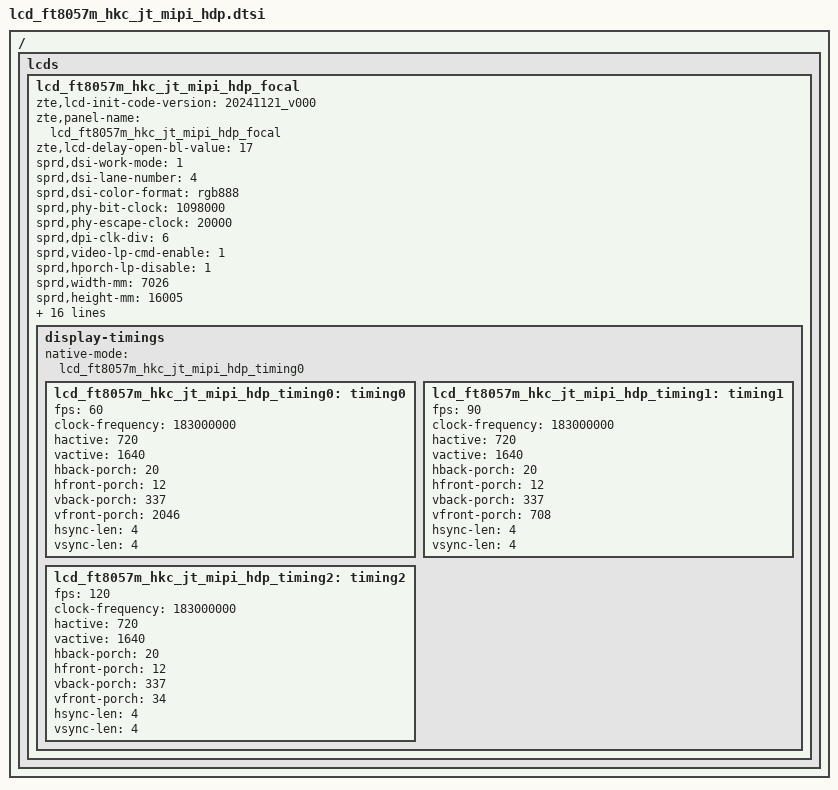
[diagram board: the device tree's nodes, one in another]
/ { 
	fragment {
		target-path = "/";
		__overlay__ {
			lcds {
				lcd_ft8057m_hkc_jt_mipi_hdp_focal: lcd_ft8057m_hkc_jt_mipi_hdp_focal {
		zte,lcd-init-code-version = "20241121_v000";
		zte,panel-name = "lcd_ft8057m_hkc_jt_mipi_hdp_focal";
		zte,lcd-delay-open-bl-value = <17>;

					sprd,dsi-work-mode = <1>;
					sprd,dsi-lane-number = <4>;
					sprd,dsi-color-format = "rgb888";

					sprd,phy-bit-clock = <1098000>;
					sprd,phy-escape-clock = <20000>;
					sprd,dpi-clk-div = <6>;
					sprd,video-lp-cmd-enable = <1>;
					sprd,hporch-lp-disable = <1>;
					sprd,width-mm = <7026>;/*zte mod for 6.67*/
					sprd,height-mm = <16005>;/*zte mod for 6.67*/

					sprd,esd-check-enable = <1>;
					sprd,esd-check-mode = <0>;
					sprd,esd-check-period = <2000>;
					sprd,esd-check-register = <0x0E>;
					sprd,esd-check-value = <0x80>;

					sprd,lcm-ic-name = "FT8057M";
					sprd,lcm-ic-vendor = "JT-HKC";
					sprd,lcm-ic-inch = "6.56";

					sprd,reset-on-sequence = <1 5>, <0 5>, <1 20>;
					sprd,reset-off-sequence = <1 5>;


					sprd,initial-command = [
23 00 00 02 00 00 
39 00 00 04 FF 80 57 01 
23 00 00 02 00 80 
39 00 00 03 FF 80 57 
23 00 00 02 00 00 
39 00 00 05 2A 00 00 02 CF 
23 00 00 02 00 00 
39 00 00 05 2B 00 00 06 67 
23 00 00 02 00 A3 
39 00 00 05 B3 06 68 00 18 
23 00 00 02 00 93 
23 00 00 02 C5 75 
23 00 00 02 00 97 
23 00 00 02 C5 75 
23 00 00 02 00 9A 
23 00 00 02 C5 41 
23 00 00 02 00 9C 
23 00 00 02 C5 41 
23 00 00 02 00 B6 
39 00 00 03 C5 61 61 
23 00 00 02 00 B8 
39 00 00 03 C5 37 37 
23 00 00 02 00 00 
39 00 00 03 D8 37 37 
//23 00 00 02 00 00 
//39 00 00 03 D9 00 AC 
//23 00 00 02 00 00 
//39 00 00 04 D9 00 AC AC 
23 00 00 02 00 82 
23 00 00 02 C5 55 
23 00 00 02 00 83 
23 00 00 02 C5 07 
23 00 00 02 00 96 
23 00 00 02 F5 19 
23 00 00 02 00 86 
23 00 00 02 F5 19 
23 00 00 02 00 94 
23 00 00 02 C5 13 
23 00 00 02 00 9B 
23 00 00 02 C5 31 
23 00 00 02 00 A3 
23 00 00 02 A5 04 
23 00 00 02 00 99 
23 00 00 02 CF 56 
23 00 00 02 00 86 
23 00 00 02 B7 80 
23 00 00 02 00 A5 
23 00 00 02 B0 0D 
23 00 00 02 00 90 
23 00 00 02 FF 00 
23 00 00 02 00 00 
39 00 00 11 E1 00 0B 15 24 2E 38 49 58 59 67 6B 81 80 6B 6B 5F 
23 00 00 02 00 10 
39 00 00 09 E1 57 4B 3C 32 2A 1B 13 0F 
23 00 00 02 00 00 
39 00 00 11 E2 00 0B 15 24 2E 38 49 58 59 67 6B 81 80 6B 6B 5F 
23 00 00 02 00 10 
39 00 00 09 E2 57 4B 3C 32 2A 1B 13 0F 
23 00 00 02 00 80 
23 00 00 02 CE 00 
23 00 00 02 00 D0 
23 00 00 02 CE 01 
23 00 00 02 00 E0 
23 00 00 02 CE 00 
23 00 00 02 00 A1 
23 00 00 02 C1 CC 
23 00 00 02 00 A5 
39 00 00 03 C1 01 43 
23 00 00 02 00 70 
39 00 00 07 C0 00 5F 01 54 00 22 
23 00 00 02 00 D1 
39 00 00 08 CE 00 14 01 01 01 3B 01 
23 00 00 02 00 E8 
39 00 00 05 CE 01 3B 01 3B 
23 00 00 02 00 B0 
39 00 00 06 C0 00 5F 01 55 22 
23 00 00 02 00 80 
39 00 00 03 C1 22 22 
23 00 00 02 00 90 
23 00 00 02 C1 02 
23 00 00 02 00 F1 
23 00 00 02 CF 78 
23 00 00 02 00 F5 
23 00 00 02 CF 00 
23 00 00 02 00 F6 
23 00 00 02 CF 78 
23 00 00 02 00 F7 
23 00 00 02 CF 11 
23 00 00 02 00 70 
39 00 00 09 CF 06 06 8E 92 02 02 3E 42 
23 00 00 02 00 C0 
39 00 00 05 CF 03 03 D8 DC 
23 00 00 02 00 C5 
39 00 00 05 CF 06 06 72 76 
23 00 00 02 00 80 
39 00 00 11 CC 00 00 1C 1C 26 26 01 01 07 09 0B 0D 0F 11 13 15 
23 00 00 02 00 90 
39 00 00 09 CC 05 03 00 00 00 00 00 00 
23 00 00 02 00 80 
39 00 00 11 CD 00 00 1C 1C 26 26 01 01 06 08 0A 0C 0E 10 12 14 
23 00 00 02 00 90 
39 00 00 09 CD 04 02 00 00 00 00 00 00 
23 00 00 02 00 A0 
39 00 00 11 CC 00 00 1C 1C 26 26 01 01 07 09 0B 0D 0F 11 13 15 
23 00 00 02 00 B0 
39 00 00 09 CC 05 03 00 00 00 00 00 00 
23 00 00 02 00 A0 
39 00 00 11 CD 00 00 1C 1C 26 26 01 01 06 08 0A 0C 0E 10 12 14 
23 00 00 02 00 B0 
39 00 00 09 CD 04 02 00 00 00 00 00 00 
23 00 00 02 00 80 
39 00 00 11 CB C1 C1 C1 C1 C1 C1 C1 C1 C1 C1 C1 C1 C1 C1 C1 C1 
23 00 00 02 00 ED 
23 00 00 02 CB C1 
23 00 00 02 00 90 
39 00 00 11 CB FC 00 00 00 00 00 00 00 00 00 FC 00 00 00 00 00 
23 00 00 02 00 EE 
23 00 00 02 CB 00 
23 00 00 02 00 90 
23 00 00 02 C3 00 
23 00 00 02 00 A0 
39 00 00 09 CB 00 00 00 00 00 00 00 00 
23 00 00 02 00 B0 
39 00 00 05 CB 54 54 15 00 
23 00 00 02 00 C0 
39 00 00 05 CB 55 55 55 55 
23 00 00 02 00 D2 
39 00 00 0C CB C3 00 C3 C3 00 C3 C3 00 C3 C3 00 
23 00 00 02 00 E0 
39 00 00 0E CB C3 C3 00 C3 C3 00 C3 C3 00 C3 C3 00 C3 
23 00 00 02 00 FA 
39 00 00 03 CB C3 00 
23 00 00 02 00 EF 
23 00 00 02 CB 01 
23 00 00 02 00 68 
39 00 00 05 C2 90 07 63 63 
23 00 00 02 00 6C 
39 00 00 05 C2 8F 07 63 63 
23 00 00 02 00 70 
39 00 00 05 C2 8E 07 63 63 
23 00 00 02 00 74 
39 00 00 05 C2 8D 07 63 63 
23 00 00 02 00 EA 
39 00 00 09 C2 12 00 12 0C 00 00 00 00 
23 00 00 02 00 8C 
39 00 00 06 C2 95 02 8E 63 94 
23 00 00 02 00 91 
39 00 00 06 C2 94 03 8E 63 94 
23 00 00 02 00 96 
39 00 00 06 C2 93 04 8E 63 94 
23 00 00 02 00 9B 
39 00 00 06 C2 92 05 8E 63 94 
23 00 00 02 00 A0 
39 00 00 06 C2 91 06 8E 63 94 
23 00 00 02 00 A5 
39 00 00 06 C2 90 07 8E 63 94 
23 00 00 02 00 AA 
39 00 00 06 C2 8F 08 8E 63 94 
23 00 00 02 00 AF 
39 00 00 06 C2 8E 09 8E 63 94 
23 00 00 02 00 B4 
39 00 00 06 C2 8D 86 8E 63 94 
23 00 00 02 00 B9 
39 00 00 06 C2 8C 85 8E 63 94 
23 00 00 02 00 BE 
39 00 00 06 C2 8B 84 8E 63 94 
23 00 00 02 00 C3 
39 00 00 06 C2 8A 83 8E 63 94 
23 00 00 02 00 C8 
39 00 00 06 C2 89 82 8E 63 94 
23 00 00 02 00 CD 
39 00 00 06 C2 88 81 8E 63 94 
23 00 00 02 00 D2 
39 00 00 06 C2 87 00 8E 63 94 
23 00 00 02 00 D7 
39 00 00 06 C2 86 01 8E 63 94 
23 00 00 02 00 DC 
39 00 00 09 C2 FF FF FF FF FF FF FF FF 
23 00 00 02 00 FC 
39 00 00 03 CB 08 80 
23 00 00 02 00 FB 
39 00 00 05 C3 93 0B 96 0A 
23 00 00 02 00 86 
39 00 00 04 C3 0F 00 00 
23 00 00 02 00 94 
39 00 00 04 C3 0F 00 00 
23 00 00 02 00 98 
23 00 00 02 C4 08 
23 00 00 02 00 90 
39 00 00 06 E9 10 FF FF FF 00 
23 00 00 02 00 85 
23 00 00 02 C4 80 
23 00 00 02 00 80 
23 00 00 02 A4 4E 
23 00 00 02 00 81 
23 00 00 02 A4 73 
23 00 00 02 00 86 
23 00 00 02 A4 B6 
23 00 00 02 00 95 
23 00 00 02 C4 80 
23 00 00 02 00 93 
23 00 00 02 C4 8F 
23 00 00 02 00 80 
23 00 00 02 B3 17 
23 00 00 02 00 CA 
39 00 00 03 C0 90 11 
23 00 00 02 00 B7 
23 00 00 02 F5 1D 
23 00 00 02 00 B1 
23 00 00 02 F5 11 
23 00 00 02 00 B0 
23 00 00 02 C5 00 
23 00 00 02 00 B3 
23 00 00 02 C5 00 
23 00 00 02 00 B2 
23 00 00 02 C5 0D 
23 00 00 02 00 B5 
23 00 00 02 C5 02 
23 00 00 02 00 C2 
23 00 00 02 F5 42 
23 00 00 02 00 80 
23 00 00 02 A4 4E 
23 00 00 02 00 93 
39 00 00 03 E9 00 00 
23 00 00 02 00 86 
39 00 00 04 C3 0F 00 00 
23 00 00 02 00 94 
39 00 00 04 C3 0F 00 00 
23 00 00 02 00 B0 
39 00 00 04 CA 02 02 0C 
39 00 00 03 51 00 00
23 00 00 02 53 2C 
23 00 00 02 55 00
23 00 00 02 00 00
39 00 00 04 FF 00 00 00
23 00 00 02 00 80
39 00 00 03 FF 00 00
23 00 00 02 35 00
23 96 00 02 11 00 
23 32 00 02 29 00 
					];
					sprd,sleep-in-command = [
						13 32 00 01 28
						13 96 00 01 10
					];
					sprd,sleep-out-command = [
						13 96 00 01 11
						13 32 00 01 29
					];

					display-timings {
						native-mode = <&lcd_ft8057m_hkc_jt_mipi_hdp_timing0>;
						lcd_ft8057m_hkc_jt_mipi_hdp_timing0: timing0 {
							fps = <60>;
							clock-frequency = <183000000>;
							hactive = <720>;
							vactive = <1640>;
							hback-porch = <20>;
							hfront-porch = <12>;
							vback-porch = <337>;
							vfront-porch = <2046>;
							hsync-len = <4>;
							vsync-len = <4>;
						};
						lcd_ft8057m_hkc_jt_mipi_hdp_timing1: timing1 {
							fps = <90>;
							clock-frequency = <183000000>;
							hactive = <720>;
							vactive = <1640>;
							hback-porch = <20>;
							hfront-porch = <12>;
							vback-porch = <337>;
							vfront-porch = <708>;
							hsync-len = <4>;
							vsync-len = <4>;
						};
						lcd_ft8057m_hkc_jt_mipi_hdp_timing2: timing2 {
							fps = <120>;
							clock-frequency = <183000000>;
							hactive = <720>;
							vactive = <1640>;
							hback-porch = <20>;
							hfront-porch = <12>;
							vback-porch = <337>;
							vfront-porch = <34>;
							hsync-len = <4>;
							vsync-len = <4>;
						};
					};
				};
			};
		};
	};
};
